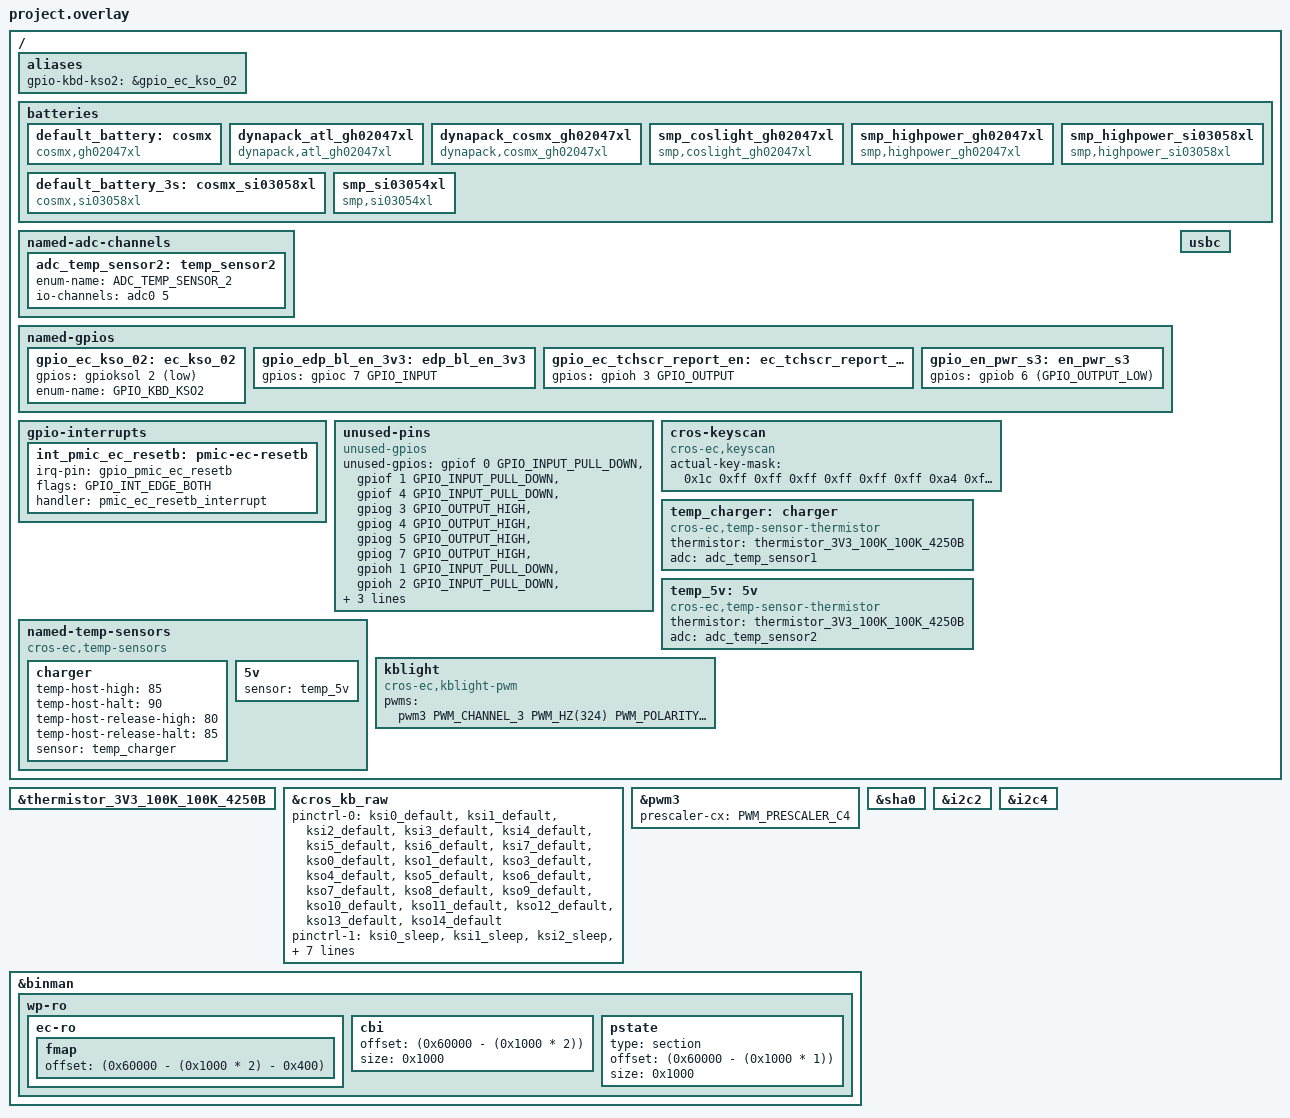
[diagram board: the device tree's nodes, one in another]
/* Copyright 2025 The ChromiumOS Authors
 * Use of this source code is governed by a BSD-style license that can be
 * found in the LICENSE file.
 */

#include <cros/cbi_flash.dtsi>
#include <cros/thermistor/thermistor.dtsi>
#include "../ite_generated.dtsi"
#include "../interrupts.dtsi"
#include "../ite_common.dtsi"
#include "../ite_keyboard.dtsi"
#include "../ite_overlay.dtsi"
#include "../ite_usbc.dtsi"
#include "../power_signal.dtsi"
#include "../usba.dtsi"
#include "cbi.dtsi"
#include "led_pins.dtsi"
#include "led_policy.dtsi"

/ {
	aliases {
		gpio-kbd-kso2 = &gpio_ec_kso_02;
	};

	batteries {
		default_battery: cosmx {
			compatible = "cosmx,gh02047xl", "battery-smart";
		};
		dynapack_atl_gh02047xl {
			compatible = "dynapack,atl_gh02047xl", "battery-smart";
		};
		dynapack_cosmx_gh02047xl {
			compatible = "dynapack,cosmx_gh02047xl", "battery-smart";
		};
		smp_coslight_gh02047xl {
			compatible = "smp,coslight_gh02047xl", "battery-smart";
		};
		smp_highpower_gh02047xl {
			compatible = "smp,highpower_gh02047xl", "battery-smart";
		};
		default_battery_3s:cosmx_si03058xl {
			compatible = "cosmx,si03058xl", "battery-smart";
		};
		smp_highpower_si03058xl {
			compatible = "smp,highpower_si03058xl", "battery-smart";
		};
		smp_si03054xl {
			compatible = "smp,si03054xl", "battery-smart";
		};
	};

	named-adc-channels {
		/delete-node/ usbc_sub_detect;

		adc_temp_sensor2: temp_sensor2 {
			enum-name = "ADC_TEMP_SENSOR_2";
			io-channels = <&adc0 5>;
		};
	};

	named-gpios {
		/delete-node/ ec_kso_02_inv;
		/delete-node/ en_pp5000_z1;
		/delete-node/ dp_aux_path_sel;
		/delete-node/ usb_c1_dp_hpd;
		/delete-node/ ec_voldn_btn_odl;
		/delete-node/ ec_volup_btn_odl;
		/delete-node/ imu_int_ec_l;
		/delete-node/ lid_360_l;
		/delete-node/ lid_accel_int_ec_l;

		gpio_ec_kso_02: ec_kso_02 {
			gpios = <&gpioksol 2 (GPIO_OUTPUT | GPIO_ACTIVE_LOW | GPIO_OUTPUT_INIT_LOW)>;
			enum-name = "GPIO_KBD_KSO2";
		};
		gpio_edp_bl_en_3v3: edp_bl_en_3v3 {
			gpios = <&gpioc 7 GPIO_INPUT>;
		};
		gpio_ec_tchscr_report_en: ec_tchscr_report_en {
			gpios = <&gpioh 3 GPIO_OUTPUT>;
		};
		gpio_en_pwr_s3: en_pwr_s3 {
			gpios = <&gpiob 6 (GPIO_OUTPUT_LOW)>;
		};
	};

	gpio-interrupts {
		/delete-node/ volume-up;
		/delete-node/ volume-down;
		/delete-node/ lid-accel;
		/delete-node/ ec-imu;
		/delete-node/ tablet_mode;

		int_pmic_ec_resetb: pmic-ec-resetb {
			irq-pin = <&gpio_pmic_ec_resetb>;
			flags = <GPIO_INT_EDGE_BOTH>;
			handler = "pmic_ec_resetb_interrupt";
		};
	};

	unused-pins {
		compatible = "unused-gpios";
		unused-gpios =
			<&gpiof 0 GPIO_INPUT_PULL_DOWN>,
			<&gpiof 1 GPIO_INPUT_PULL_DOWN>,
			<&gpiof 4 GPIO_INPUT_PULL_DOWN>,
			<&gpiog 3 GPIO_OUTPUT_HIGH>,
			<&gpiog 4 GPIO_OUTPUT_HIGH>,
			<&gpiog 5 GPIO_OUTPUT_HIGH>,
			<&gpiog 7 GPIO_OUTPUT_HIGH>,
			<&gpioh 1 GPIO_INPUT_PULL_DOWN>,
			<&gpioh 2 GPIO_INPUT_PULL_DOWN>,
			<&gpioi 1 GPIO_INPUT_PULL_DOWN>,
			<&gpioi 5 GPIO_INPUT_PULL_DOWN>,
			<&gpioj 2 GPIO_INPUT_PULL_DOWN>;
	};

	cros-keyscan {
		compatible = "cros-ec,keyscan";

		actual-key-mask = <
			0x1c /* C0 */
			0xff /* C1 */
			0xff /* C2 */
			0xff /* C3 */
			0xff /* C4 */
			0xff /* C5 */
			0xff /* C6 */
			0xa4 /* C7 */
			0xff /* C8 */
			0xf6 /* C9 */
			0x55 /* C10 */
			0xfe /* C11 */
			0xff /* C12 */
			0xff /* C13 */
			0xff /* C14 */
		>;
	};

	temp_charger: charger {
		compatible = "cros-ec,temp-sensor-thermistor";
		thermistor = <&thermistor_3V3_100K_100K_4250B>;
		adc = <&adc_temp_sensor1>;
	};

	temp_5v: 5v {
		compatible = "cros-ec,temp-sensor-thermistor";
		thermistor = <&thermistor_3V3_100K_100K_4250B>;
		adc = <&adc_temp_sensor2>;
	};

	named-temp-sensors {
		compatible = "cros-ec,temp-sensors";
		charger {
			temp-host-high = <85>;
			temp-host-halt = <90>;
			temp-host-release-high = <80>;
			temp-host-release-halt = <85>;
			sensor = <&temp_charger>;
		};
		5v {
			sensor = <&temp_5v>;
		};
	};

	usbc {
		/delete-node/ port1@1;
	};

	kblight {
		compatible = "cros-ec,kblight-pwm";
		/*
		 * Use 324 Hz so that 32Khz clock source is used,
		 * which is not gated in power saving mode.
		 */
		pwms = <&pwm3 PWM_CHANNEL_3 PWM_HZ(324) PWM_POLARITY_NORMAL>;
	};
};


&thermistor_3V3_100K_100K_4250B {
	status = "okay";
};

&cros_kb_raw {
	pinctrl-0 = <&ksi0_default
		     &ksi1_default
		     &ksi2_default
		     &ksi3_default
		     &ksi4_default
		     &ksi5_default
		     &ksi6_default
		     &ksi7_default
		     &kso0_default
		     &kso1_default
		     &kso3_default
		     &kso4_default
		     &kso5_default
		     &kso6_default
		     &kso7_default
		     &kso8_default
		     &kso9_default
		     &kso10_default
		     &kso11_default
		     &kso12_default
		     &kso13_default
		     &kso14_default>;
	pinctrl-1 = <&ksi0_sleep
		     &ksi1_sleep
		     &ksi2_sleep
		     &ksi3_sleep
		     &ksi4_sleep
		     &ksi5_sleep
		     &ksi6_sleep
		     &ksi7_sleep
		     &kso0_sleep
		     &kso1_sleep
		     &kso2_sleep
		     &kso3_sleep
		     &kso4_sleep
		     &kso5_sleep
		     &kso6_sleep
		     &kso7_sleep
		     &kso8_sleep
		     &kso9_sleep
		     &kso10_sleep
		     &kso11_sleep
		     &kso12_sleep
		     &kso13_sleep
		     &kso14_sleep>;
	pinctrl-names = "default", "sleep";
};

&pwm3 {
	prescaler-cx = <PWM_PRESCALER_C4>;
};

&sha0 {
	status = "okay";
};

/*
 * When CBI in flash is enabled, setup RO flash layout as follows:
 *   RO binary:    0x00000:0x5DFFF
 *   FMAP:         0x5DC00:0x5DFFF
 *   CBI flash:    0x5E000:0x5EFFF
 *   PSTATE block: 0x5F000:0x5FFFF
 */
&binman {
	wp-ro {
		/*
		 * Delete the pstate node so that we can force it to be the
		 * last sub-section. binman doesn't handle sub-sections with
		 * out of order offsets.
		 */
		 /delete-node/ pstate;

		 ec-ro {
			fmap {
				offset =  <(0x60000 - (0x1000 * 2) - 0x400)>;
				/*
				* don't specify 'size = <0x400>' here so
				* it is auto-assigned to the fmap size.
				*/
			};
		};
		cbi {
			offset = <(0x60000 - (0x1000 * 2))>;
			size = <0x1000>;
		};
		pstate {
			type = "section";
			offset = <(0x60000 - (0x1000 * 1))>;
			size = <0x1000>;
		};
	};
};

&i2c2 {
	/delete-node/ rts54-pdc@67;
};

&i2c4 {
	/delete-node/ ps8747-mux-1@10;
	/delete-node/ tusb546-mux-0@44;
};
